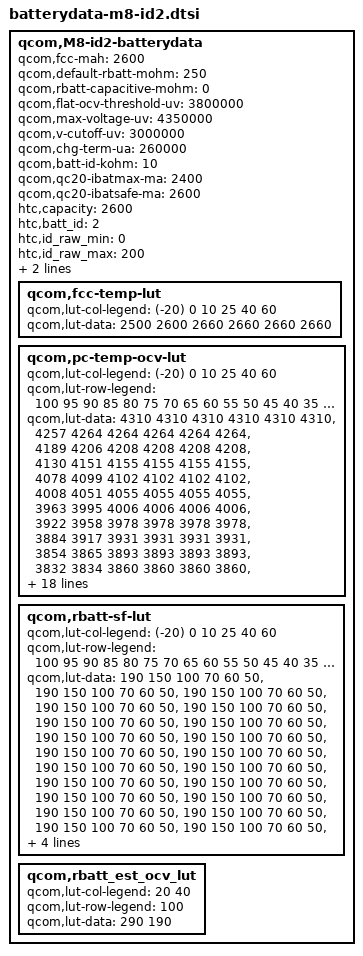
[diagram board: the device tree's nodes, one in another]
	qcom,M8-id2-batterydata {
	qcom,fcc-mah = <2600>;
	qcom,default-rbatt-mohm = <250>;
	qcom,rbatt-capacitive-mohm = <0>;
	qcom,flat-ocv-threshold-uv = <3800000>;
	qcom,max-voltage-uv = <4350000>;
	qcom,v-cutoff-uv = <3000000>;
	qcom,chg-term-ua = <260000>;
	qcom,batt-id-kohm = <10>;
	qcom,qc20-ibatmax-ma = <2400>;
	qcom,qc20-ibatsafe-ma = <2600>;
	htc,capacity = <2600>;
	htc,batt_id = <2>;
	htc,id_raw_min = <0>;
	htc,id_raw_max = <200>;
	htc,type = <1>;
	htc,model_name = "B0P6B100";

	qcom,fcc-temp-lut {
		qcom,lut-col-legend = <(-20) 0 10 25 40 60>;
		qcom,lut-data = <2500 2600 2660 2660 2660 2660>;
	};

	qcom,pc-temp-ocv-lut {
		qcom,lut-col-legend = <(-20) 0 10 25 40 60>;
		qcom,lut-row-legend = <100 95 90 85 80 75 70 65 60 55 50 45 40 35 30 25 20 15 10 9 8 7 6 5 4 3 2 1 0>;
		qcom,lut-data = <4310 4310 4310 4310 4310 4310>,
				<4257 4264 4264 4264 4264 4264>,
				<4189 4206 4208 4208 4208 4208>,
				<4130 4151 4155 4155 4155 4155>,
				<4078 4099 4102 4102 4102 4102>,
				<4008 4051 4055 4055 4055 4055>,
				<3963 3995 4006 4006 4006 4006>,
				<3922 3958 3978 3978 3978 3978>,
				<3884 3917 3931 3931 3931 3931>,
				<3854 3865 3893 3893 3893 3893>,
				<3832 3834 3860 3860 3860 3860>,
				<3817 3817 3830 3830 3830 3830>,
				<3806 3802 3809 3809 3809 3809>,
				<3796 3789 3793 3793 3793 3793>,
				<3786 3784 3781 3781 3781 3781>,
				<3773 3775 3768 3768 3768 3768>,
				<3757 3751 3735 3735 3735 3735>,
				<3739 3727 3700 3700 3700 3700>,
				<3714 3692 3682 3682 3682 3682>,
				<3707 3678 3677 3677 3677 3677>,
				<3700 3664 3668 3668 3668 3668>,
				<3692 3650 3660 3660 3660 3660>,
				<3685 3636 3630 3630 3630 3630>,
				<3678 3626 3610 3610 3610 3610>,
				<3624 3538 3500 3500 3500 3500>,
				<3571 3453 3420 3420 3420 3420>,
				<3518 3368 3280 3280 3280 3240>,
				<3465 3283 3117 3117 3117 3117>,
				<3411 3198 3000 3000 3000 3000>;
	};

	qcom,rbatt-sf-lut {
		qcom,lut-col-legend = <(-20) 0 10 25 40 60>;
		qcom,lut-row-legend = <100 95 90 85 80 75 70 65 60 55 50 45 40 35 30 25 20 15 10 9 8 7 6 5 4 3 2 1>;
		qcom,lut-data = <190 150 100 70 60 50>,
				<190 150 100 70 60 50>,
				<190 150 100 70 60 50>,
				<190 150 100 70 60 50>,
				<190 150 100 70 60 50>,
				<190 150 100 70 60 50>,
				<190 150 100 70 60 50>,
				<190 150 100 70 60 50>,
				<190 150 100 70 60 50>,
				<190 150 100 70 60 50>,
				<190 150 100 70 60 50>,
				<190 150 100 70 60 50>,
				<190 150 100 70 60 50>,
				<190 150 100 70 60 50>,
				<190 150 100 70 60 50>,
				<190 150 100 70 60 50>,
				<190 150 100 70 60 50>,
				<190 150 100 70 60 50>,
				<190 150 100 70 60 50>,
				<190 150 100 70 60 50>,
				<190 150 100 70 60 50>,
				<190 150 100 70 60 50>,
				<190 150 100 70 60 50>,
				<190 150 100 70 60 50>,
				<190 150 100 70 60 50>,
				<190 150 100 70 60 50>,
				<190 150 100 70 60 50>,
				<190 150 100 70 60 50>;
		};

	qcom,rbatt_est_ocv_lut {
		qcom,lut-col-legend = <20 40>;
		qcom,lut-row-legend = <100>;
		qcom,lut-data = <290 190>;
		};
	};
